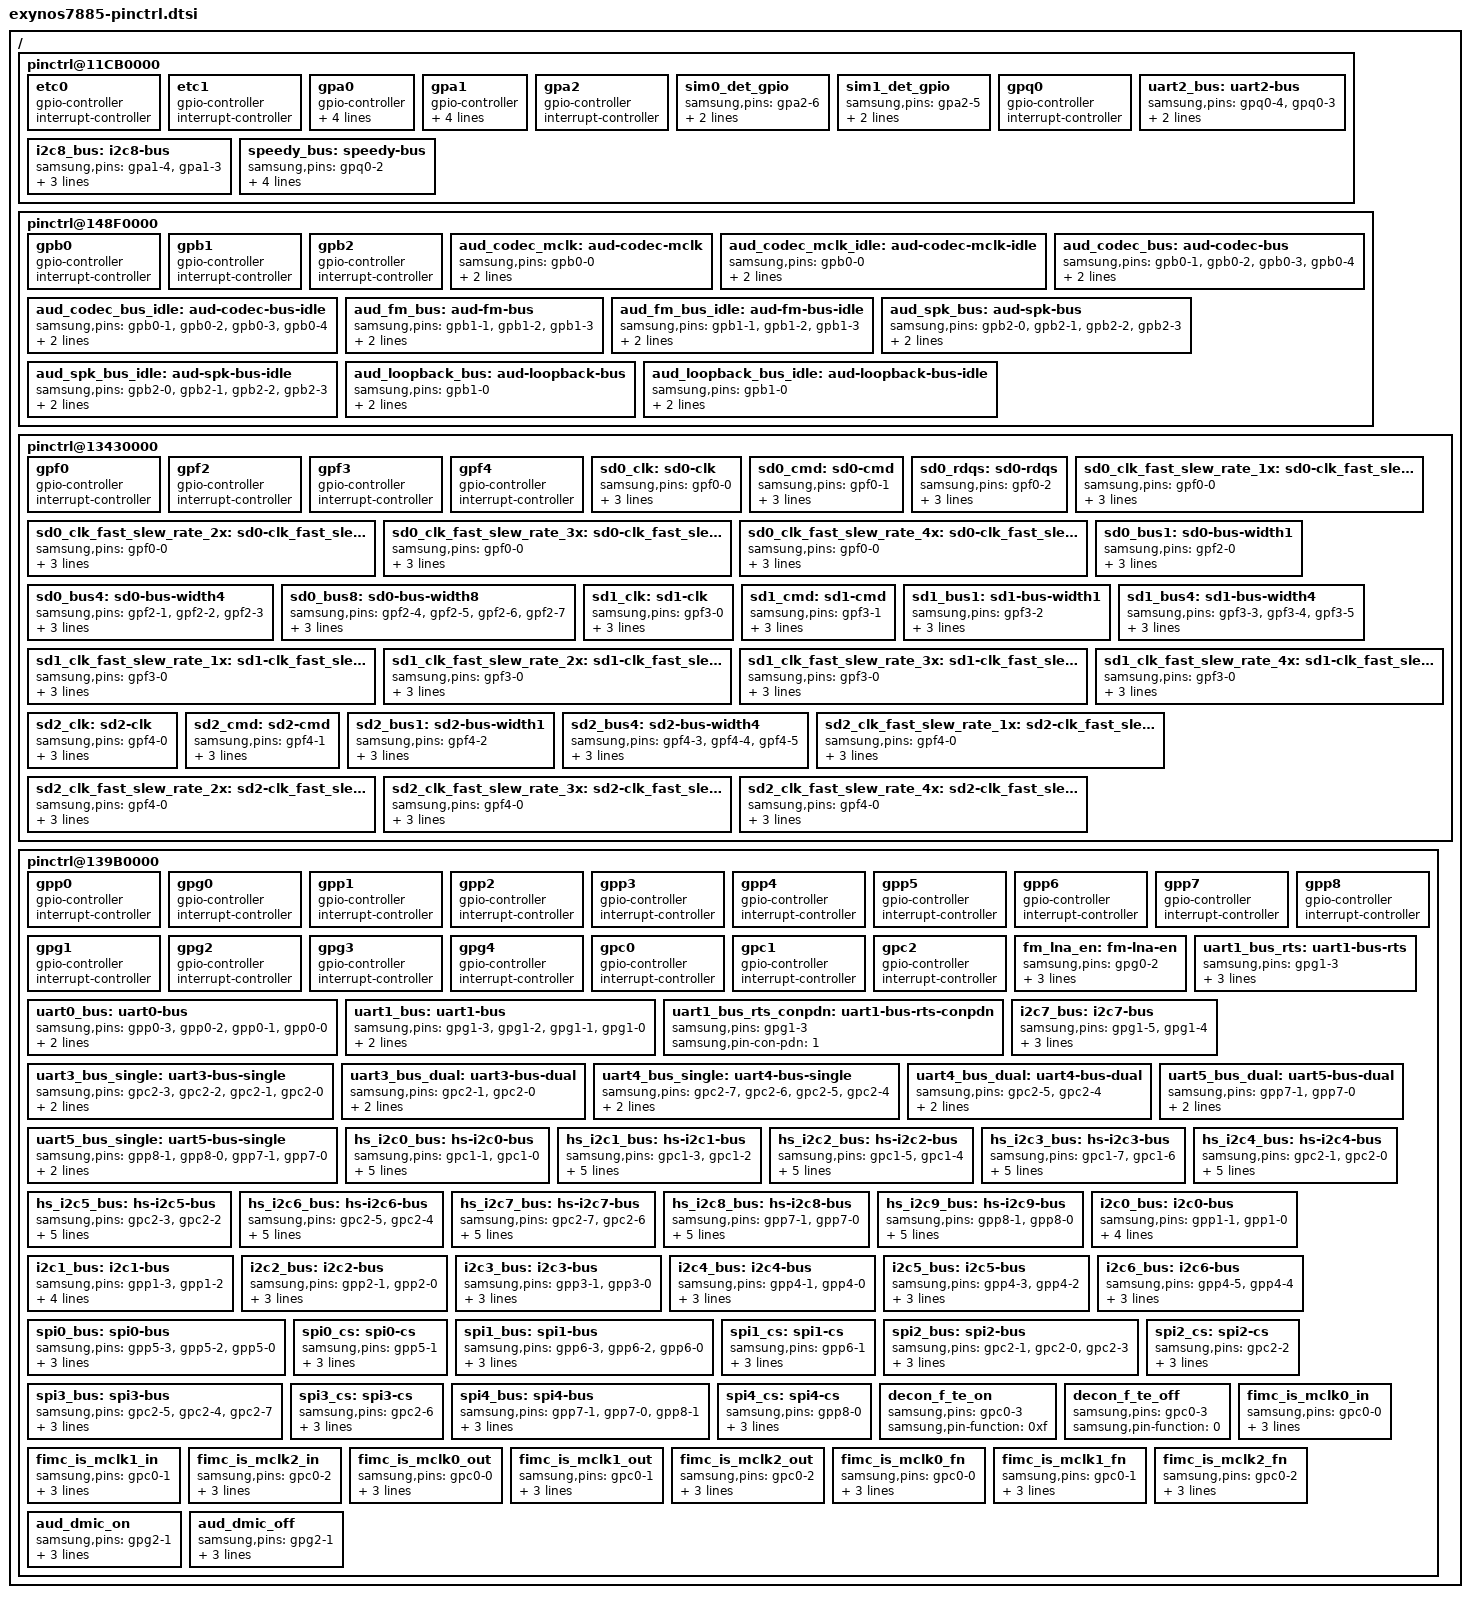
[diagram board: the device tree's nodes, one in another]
/*
 * Samsung's Exynos7885 SoC pin-mux and pin-config device tree source
 *
 * Copyright (c) 2017 Samsung Electronics Co., Ltd.
 *		http://www.samsung.com
 *
 * Samsung's Exynos7885 SoC pin-mux and pin-config options are listed as device
 * tree nodes are listed in this file.
 *
 * This program is free software; you can redistribute it and/or modify
 * it under the terms of the GNU General Public License version 2 as
 * published by the Free Software Foundation.
*/

/ {
	/* ALIVE */
	pinctrl@11CB0000 {
                etc0: etc0 {
                        gpio-controller;
                        #gpio-cells = <2>;

                        interrupt-controller;
                        #interrupt-cells = <2>;
                };

                etc1: etc1 {
                        gpio-controller;
                        #gpio-cells = <2>;

                        interrupt-controller;
                        #interrupt-cells = <2>;
                };

		gpa0: gpa0 {
			gpio-controller;
			#gpio-cells = <2>;

			interrupt-controller;
			#interrupt-cells = <2>;
			interrupt-parent = <&gic>;
			interrupts = <0 0 0>, <0 1 0>, <0 2 0>, <0 3 0>,
				     <0 4 0>, <0 5 0>, <0 6 0>, <0 7 0>;
		};

		gpa1: gpa1 {
			gpio-controller;
			#gpio-cells = <2>;

			interrupt-controller;
			#interrupt-cells = <3>;
			interrupt-parent = <&gic>;
			interrupts = <0 8 0>, <0 9 0>, <0 10 0>, <0 11 0>,
				     <0 12 0>, <0 13 0>, <0 14 0>, <0 15 0>;
		};

		gpa2: gpa2 {
			gpio-controller;
			#gpio-cells = <2>;

			interrupt-controller;
			#interrupt-cells = <2>;
		};

		sim0_det_gpio: sim0_det_gpio {
			samsung,pins = "gpa2-6";
			samsung,pin-function = <15>;
			samsung,pin-pud = <0>;
		};

		sim1_det_gpio: sim1_det_gpio {
			samsung,pins = "gpa2-5";
			samsung,pin-function = <15>;
			samsung,pin-pud = <0>;
		};

		gpq0: gpq0 {
			gpio-controller;
			#gpio-cells = <2>;

			interrupt-controller;
			#interrupt-cells = <2>;
		};

		/* UART_DEBUG */
		uart2_bus: uart2-bus {
			samsung,pins = "gpq0-4", "gpq0-3";
			samsung,pin-function = <2>;
			samsung,pin-pud = <0>;
		};

		/* I2C_APM */
		i2c8_bus: i2c8-bus {
			samsung,pins = "gpa1-4", "gpa1-3";
			samsung,pin-function = <2>;
			samsung,pin-pud = <3>;
			samsung,pin-drv = <0>;
		};

		speedy_bus: speedy-bus {
			samsung,pins = "gpq0-2";
			samsung,pin-function = <2>;
			samsung,pin-con-pdn = <3>;
			samsung,pin-pud = <3>;
			samsung,pin-drv = <0>;
		};
	};

	/* DISPAUD */
	pinctrl@148F0000 {
		gpb0: gpb0 {
			gpio-controller;
			#gpio-cells = <2>;

			interrupt-controller;
			#interrupt-cells = <2>;
		};

		gpb1: gpb1 {
			gpio-controller;
			#gpio-cells = <2>;

			interrupt-controller;
			#interrupt-cells = <2>;
		};

		gpb2: gpb2 {
			gpio-controller;
			#gpio-cells = <2>;

			interrupt-controller;
			#interrupt-cells = <2>;
		};

		aud_codec_mclk: aud-codec-mclk {
			samsung,pins = "gpb0-0";
			samsung,pin-function = <2>;
			samsung,pin-pud = <1>;
		};

		aud_codec_mclk_idle: aud-codec-mclk-idle {
			samsung,pins = "gpb0-0";
			samsung,pin-function = <0>;
			samsung,pin-pud = <1>;
		};

		aud_codec_bus: aud-codec-bus {
			samsung,pins = "gpb0-1", "gpb0-2", "gpb0-3", "gpb0-4";
			samsung,pin-function = <2>;
			samsung,pin-pud = <1>;
		};

		aud_codec_bus_idle: aud-codec-bus-idle {
			samsung,pins = "gpb0-1", "gpb0-2", "gpb0-3", "gpb0-4";
			samsung,pin-function = <0>;
			samsung,pin-pud = <1>;
		};

		aud_fm_bus: aud-fm-bus {
			samsung,pins = "gpb1-1", "gpb1-2", "gpb1-3";
			samsung,pin-function = <2>;
			samsung,pin-pud = <1>;
		};

		aud_fm_bus_idle: aud-fm-bus-idle {
			samsung,pins = "gpb1-1", "gpb1-2", "gpb1-3";
			samsung,pin-function = <0>;
			samsung,pin-pud = <1>;
		};

		aud_spk_bus: aud-spk-bus {
			samsung,pins = "gpb2-0", "gpb2-1", "gpb2-2", "gpb2-3";
			samsung,pin-function = <2>;
			samsung,pin-pud = <1>;
		};

		aud_spk_bus_idle: aud-spk-bus-idle {
			samsung,pins = "gpb2-0", "gpb2-1", "gpb2-2", "gpb2-3";
			samsung,pin-function = <0>;
			samsung,pin-pud = <1>;
		};

		aud_loopback_bus: aud-loopback-bus{
			samsung,pins = "gpb1-0";
			samsung,pin-function = <2>;
			samsung,pin-pud = <1>;
		};

		aud_loopback_bus_idle: aud-loopback-bus-idle{
			samsung,pins = "gpb1-0";
			samsung,pin-function = <0>;
			samsung,pin-pud = <1>;
		};
	};


	/* FSYS */
	pinctrl@13430000 {
		gpf0: gpf0 {
			gpio-controller;
			#gpio-cells = <2>;

			interrupt-controller;
			#interrupt-cells = <2>;
		};

		gpf2: gpf2 {
			gpio-controller;
			#gpio-cells = <2>;

			interrupt-controller;
			#interrupt-cells = <2>;
		};

		gpf3: gpf3 {
			gpio-controller;
			#gpio-cells = <2>;

			interrupt-controller;
			#interrupt-cells = <2>;
		};

		gpf4: gpf4 {
			gpio-controller;
			#gpio-cells = <2>;

			interrupt-controller;
			#interrupt-cells = <2>;
		};

		sd0_clk: sd0-clk {
			samsung,pins = "gpf0-0";
			samsung,pin-function = <2>;
			samsung,pin-pud = <0>;
			samsung,pin-drv = <3>;
		};

		sd0_cmd: sd0-cmd {
			samsung,pins = "gpf0-1";
			samsung,pin-function = <2>;
			samsung,pin-pud = <3>;
			samsung,pin-drv = <3>;
		};

		sd0_rdqs: sd0-rdqs {
			samsung,pins = "gpf0-2";
			samsung,pin-function = <2>;
			samsung,pin-pud = <1>;
			samsung,pin-drv = <3>;
		};

		sd0_clk_fast_slew_rate_1x: sd0-clk_fast_slew_rate_1x {
			samsung,pins = "gpf0-0";
			samsung,pin-function = <2>;
			samsung,pin-pud = <0>;
			samsung,pin-drv = <0>;
		};

		sd0_clk_fast_slew_rate_2x: sd0-clk_fast_slew_rate_2x {
			samsung,pins = "gpf0-0";
			samsung,pin-function = <2>;
			samsung,pin-pud = <0>;
			samsung,pin-drv = <1>;
		};

		sd0_clk_fast_slew_rate_3x: sd0-clk_fast_slew_rate_3x {
			samsung,pins = "gpf0-0";
			samsung,pin-function = <2>;
			samsung,pin-pud = <0>;
			samsung,pin-drv = <2>;
		};

		sd0_clk_fast_slew_rate_4x: sd0-clk_fast_slew_rate_4x {
			samsung,pins = "gpf0-0";
			samsung,pin-function = <2>;
			samsung,pin-pud = <0>;
			samsung,pin-drv = <3>;
		};

		sd0_bus1: sd0-bus-width1 {
			samsung,pins = "gpf2-0";
			samsung,pin-function = <2>;
			samsung,pin-pud = <3>;
			samsung,pin-drv = <3>;
		};

		sd0_bus4: sd0-bus-width4 {
			samsung,pins = "gpf2-1", "gpf2-2", "gpf2-3";
			samsung,pin-function = <2>;
			samsung,pin-pud = <3>;
			samsung,pin-drv = <3>;
		};

		sd0_bus8: sd0-bus-width8 {
			samsung,pins = "gpf2-4", "gpf2-5", "gpf2-6", "gpf2-7";
			samsung,pin-function = <2>;
			samsung,pin-pud = <3>;
			samsung,pin-drv = <3>;
		};

		sd1_clk: sd1-clk {
			samsung,pins = "gpf3-0";
			samsung,pin-function = <2>;
			samsung,pin-pud = <0>;
			samsung,pin-drv = <2>;
		};

		sd1_cmd: sd1-cmd {
			samsung,pins = "gpf3-1";
			samsung,pin-function = <2>;
			samsung,pin-pud = <3>;
			samsung,pin-drv = <2>;
		};

		sd1_bus1: sd1-bus-width1 {
			samsung,pins = "gpf3-2";
			samsung,pin-function = <2>;
			samsung,pin-pud = <3>;
			samsung,pin-drv = <2>;
		};

		sd1_bus4: sd1-bus-width4 {
			samsung,pins = "gpf3-3", "gpf3-4", "gpf3-5";
			samsung,pin-function = <2>;
			samsung,pin-pud = <3>;
			samsung,pin-drv = <2>;
		};

		sd1_clk_fast_slew_rate_1x: sd1-clk_fast_slew_rate_1x {
			samsung,pins = "gpf3-0";
			samsung,pin-function = <2>;
			samsung,pin-pud = <0>;
			samsung,pin-drv = <0>;
		};

		sd1_clk_fast_slew_rate_2x: sd1-clk_fast_slew_rate_2x {
			samsung,pins = "gpf3-0";
			samsung,pin-function = <2>;
			samsung,pin-pud = <0>;
			samsung,pin-drv = <1>;
		};

		sd1_clk_fast_slew_rate_3x: sd1-clk_fast_slew_rate_3x {
			samsung,pins = "gpf3-0";
			samsung,pin-function = <2>;
			samsung,pin-pud = <0>;
			samsung,pin-drv = <2>;
		};

		sd1_clk_fast_slew_rate_4x: sd1-clk_fast_slew_rate_4x {
			samsung,pins = "gpf3-0";
			samsung,pin-function = <2>;
			samsung,pin-pud = <0>;
			samsung,pin-drv = <3>;
		};

		sd2_clk: sd2-clk {
			samsung,pins = "gpf4-0";
			samsung,pin-function = <2>;
			samsung,pin-pud = <0>;
			samsung,pin-drv = <2>;
		};

		sd2_cmd: sd2-cmd {
			samsung,pins = "gpf4-1";
			samsung,pin-function = <2>;
			samsung,pin-pud = <3>;
			samsung,pin-drv = <2>;
		};

		sd2_bus1: sd2-bus-width1 {
			samsung,pins = "gpf4-2";
			samsung,pin-function = <2>;
			samsung,pin-pud = <3>;
			samsung,pin-drv = <2>;
		};

		sd2_bus4: sd2-bus-width4 {
			samsung,pins = "gpf4-3", "gpf4-4", "gpf4-5";
			samsung,pin-function = <2>;
			samsung,pin-pud = <3>;
			samsung,pin-drv = <2>;
		};

		sd2_clk_fast_slew_rate_1x: sd2-clk_fast_slew_rate_1x {
			samsung,pins = "gpf4-0";
			samsung,pin-function = <2>;
			samsung,pin-pud = <0>;
			samsung,pin-drv = <0>;
		};

		sd2_clk_fast_slew_rate_2x: sd2-clk_fast_slew_rate_2x {
			samsung,pins = "gpf4-0";
			samsung,pin-function = <2>;
			samsung,pin-pud = <0>;
			samsung,pin-drv = <1>;
		};

		sd2_clk_fast_slew_rate_3x: sd2-clk_fast_slew_rate_3x {
			samsung,pins = "gpf4-0";
			samsung,pin-function = <2>;
			samsung,pin-pud = <0>;
			samsung,pin-drv = <2>;
		};

		sd2_clk_fast_slew_rate_4x: sd2-clk_fast_slew_rate_4x {
			samsung,pins = "gpf4-0";
			samsung,pin-function = <2>;
			samsung,pin-pud = <0>;
			samsung,pin-drv = <3>;
		};
	};

	/* TOP */
	pinctrl@139B0000 {
		gpp0: gpp0 {
			gpio-controller;
			#gpio-cells = <2>;

			interrupt-controller;
			#interrupt-cells = <2>;
		};

		gpg0: gpg0 {
			gpio-controller;
			#gpio-cells = <2>;

			interrupt-controller;
			#interrupt-cells = <2>;
		};

		gpp1: gpp1 {
			gpio-controller;
			#gpio-cells = <2>;

			interrupt-controller;
			#interrupt-cells = <2>;
		};

		gpp2: gpp2 {
			gpio-controller;
			#gpio-cells = <2>;

			interrupt-controller;
			#interrupt-cells = <2>;
		};

		gpp3: gpp3 {
			gpio-controller;
			#gpio-cells = <2>;

			interrupt-controller;
			#interrupt-cells = <2>;
		};

		gpp4: gpp4 {
			gpio-controller;
			#gpio-cells = <2>;

			interrupt-controller;
			#interrupt-cells = <2>;
		};

		gpp5: gpp5 {
			gpio-controller;
			#gpio-cells = <2>;

			interrupt-controller;
			#interrupt-cells = <2>;
		};

		gpp6: gpp6 {
			gpio-controller;
			#gpio-cells = <2>;

			interrupt-controller;
			#interrupt-cells = <2>;
		};

		gpp7: gpp7 {
			gpio-controller;
			#gpio-cells = <2>;

			interrupt-controller;
			#interrupt-cells = <2>;
		};

		gpp8: gpp8 {
			gpio-controller;
			#gpio-cells = <2>;

			interrupt-controller;
			#interrupt-cells = <2>;
		};

		gpg1: gpg1 {
			gpio-controller;
			#gpio-cells = <2>;

			interrupt-controller;
			#interrupt-cells = <2>;
		};

		gpg2: gpg2 {
			gpio-controller;
			#gpio-cells = <2>;

			interrupt-controller;
			#interrupt-cells = <2>;
		};

		gpg3: gpg3 {
			gpio-controller;
			#gpio-cells = <2>;

			interrupt-controller;
			#interrupt-cells = <2>;
		};

		gpg4: gpg4 {
			gpio-controller;
			#gpio-cells = <2>;

			interrupt-controller;
			#interrupt-cells = <2>;
		};

		gpc0: gpc0 {
			gpio-controller;
			#gpio-cells = <2>;

			interrupt-controller;
			#interrupt-cells = <2>;
		};

		gpc1: gpc1 {
			gpio-controller;
			#gpio-cells = <2>;

			interrupt-controller;
			#interrupt-cells = <2>;
		};

		gpc2: gpc2 {
			gpio-controller;
			#gpio-cells = <2>;

			interrupt-controller;
			#interrupt-cells = <2>;
		};

		fm_lna_en: fm-lna-en {
			samsung,pins = "gpg0-2";
			samsung,pin-function = <1>;
			samsung,pin-pud = <0>;
			samsung,pin-val = <0>;
		};

		/* UART_HEALTH */
		uart0_bus: uart0-bus {
			samsung,pins = "gpp0-3", "gpp0-2", "gpp0-1", "gpp0-0";
			samsung,pin-function = <2>;
			samsung,pin-pud = <0>;
		   };

		/* UART_BTWIFIFM */
		uart1_bus: uart1-bus {
			samsung,pins = "gpg1-3", "gpg1-2", "gpg1-1", "gpg1-0";
			samsung,pin-function = <2>;
			samsung,pin-pud = <0>;
		};

		uart1_bus_rts_conpdn: uart1-bus-rts-conpdn{
			samsung,pins = "gpg1-3";
			samsung,pin-con-pdn = <1>;
		};

		uart1_bus_rts: uart1-bus-rts {
			samsung,pins = "gpg1-3";
			samsung,pin-function = <1>;
			samsung,pin-pud = <0>;
			samsung,pin-val = <1>;
		};

		/* I2C_BUS */
		i2c7_bus: i2c7-bus {
			samsung,pins = "gpg1-5", "gpg1-4";
			samsung,pin-function = <2>;
			samsung,pin-pud = <3>;
			samsung,pin-drv = <0>;
		};

		/* USI0 */
		uart3_bus_single: uart3-bus-single {
			samsung,pins = "gpc2-3", "gpc2-2", "gpc2-1", "gpc2-0";
			samsung,pin-function = <2>;
			samsung,pin-pud = <0>;
		  };

		/* USI0 */
		uart3_bus_dual: uart3-bus-dual {
			samsung,pins = "gpc2-1", "gpc2-0";
			samsung,pin-function = <2>;
			samsung,pin-pud = <0>;
		};

		/* USI1 */
		uart4_bus_single: uart4-bus-single {
			samsung,pins = "gpc2-7", "gpc2-6", "gpc2-5", "gpc2-4";
			samsung,pin-function = <2>;
			samsung,pin-pud = <0>;
		  };

		/* USI1 */
		uart4_bus_dual: uart4-bus-dual {
			samsung,pins = "gpc2-5", "gpc2-4";
			samsung,pin-function = <2>;
			samsung,pin-pud = <0>;
		};

		/* USI2 */
		uart5_bus_single: uart5-bus-single {
			samsung,pins = "gpp8-1", "gpp8-0", "gpp7-1", "gpp7-0";
			samsung,pin-function = <2>;
			samsung,pin-pud = <0>;
		  };

		/* USI2 */
		uart5_bus_dual: uart5-bus-dual {
			samsung,pins = "gpp7-1", "gpp7-0";
			samsung,pin-function = <2>;
			samsung,pin-pud = <0>;
		};

		/* HSI2C_REARSENSOR */
		hs_i2c0_bus: hs-i2c0-bus {
			samsung,pins = "gpc1-1", "gpc1-0";
			samsung,pin-function = <2>;
			samsung,pin-con-pdn = <1>;
			samsung,pin-pud-pdn = <3>;
			samsung,pin-pud = <0>;
			samsung,pin-drv = <0>;
		};

		/* HSI2C_REARAF */
		hs_i2c1_bus: hs-i2c1-bus {
			samsung,pins = "gpc1-3", "gpc1-2";
			samsung,pin-function = <2>;
			samsung,pin-pud = <0>;
			samsung,pin-drv = <0>;
			samsung,pin-con-pdn = <1>;
			samsung,pin-pud-pdn = <3>;
		};

		/* HSI2C_FRONTSENSOR */
		hs_i2c2_bus: hs-i2c2-bus {
			samsung,pins = "gpc1-5", "gpc1-4";
			samsung,pin-function = <2>;
			samsung,pin-pud = <0>;
			samsung,pin-drv = <0>;
			samsung,pin-con-pdn = <1>;
			samsung,pin-pud-pdn = <3>;
		};

		/* HSI2C_REARSENSOR */
		hs_i2c3_bus: hs-i2c3-bus {
			samsung,pins = "gpc1-7", "gpc1-6";
			samsung,pin-function = <2>;
			samsung,pin-pud = <0>;
			samsung,pin-drv = <0>;
			samsung,pin-con-pdn = <1>;
			samsung,pin-pud-pdn = <3>;
		};

		/* USI0_CH0 */
		hs_i2c4_bus: hs-i2c4-bus {
			samsung,pins = "gpc2-1", "gpc2-0";
			samsung,pin-function = <2>;
			samsung,pin-pud = <0>;
			samsung,pin-drv = <0>;
			samsung,pin-con-pdn = <1>;
			samsung,pin-pud-pdn = <3>;
		};

		/* USI0_CH1 */
		hs_i2c5_bus: hs-i2c5-bus {
			samsung,pins = "gpc2-3", "gpc2-2";
			samsung,pin-function = <2>;
			samsung,pin-pud = <0>;
			samsung,pin-drv = <0>;
			samsung,pin-con-pdn = <1>;
			samsung,pin-pud-pdn = <3>;
		};

		/* USI1_CH0 */
		hs_i2c6_bus: hs-i2c6-bus {
			samsung,pins = "gpc2-5", "gpc2-4";
			samsung,pin-function = <2>;
			samsung,pin-pud = <0>;
			samsung,pin-drv = <0>;
			samsung,pin-con-pdn = <1>;
			samsung,pin-pud-pdn = <3>;
		};

		/* USI1_CH1 */
		hs_i2c7_bus: hs-i2c7-bus {
			samsung,pins = "gpc2-7", "gpc2-6";
			samsung,pin-function = <2>;
			samsung,pin-pud = <0>;
			samsung,pin-drv = <0>;
			samsung,pin-con-pdn = <1>;
			samsung,pin-pud-pdn = <3>;
		};

		/* USI2_CH0 */
		hs_i2c8_bus: hs-i2c8-bus {
			samsung,pins = "gpp7-1", "gpp7-0";
			samsung,pin-function = <2>;
			samsung,pin-pud = <0>;
			samsung,pin-drv = <0>;
			samsung,pin-con-pdn = <1>;
			samsung,pin-pud-pdn = <3>;
		};

		/* USI2_CH1 */
		hs_i2c9_bus: hs-i2c9-bus {
			samsung,pins = "gpp8-1", "gpp8-0";
			samsung,pin-function = <2>;
			samsung,pin-pud = <0>;
			samsung,pin-drv = <0>;
			samsung,pin-con-pdn = <1>;
			samsung,pin-pud-pdn = <3>;
		};

		/* I2C_FUELGAUGE */
		i2c0_bus: i2c0-bus {
			samsung,pins = "gpp1-1", "gpp1-0";
			samsung,pin-function = <2>;
			samsung,pin-con-pdn = <3>;
			samsung,pin-pud = <3>;
			samsung,pin-drv = <0>;
		};

		/* I2C_CHARGER */
		i2c1_bus: i2c1-bus {
			samsung,pins = "gpp1-3", "gpp1-2";
			samsung,pin-function = <2>;
			samsung,pin-con-pdn = <3>;
			samsung,pin-pud = <3>;
			samsung,pin-drv = <0>;
		};

		/* I2C_TOUCHKEY */
		i2c2_bus: i2c2-bus {
			samsung,pins = "gpp2-1", "gpp2-0";
			samsung,pin-function = <2>;
			samsung,pin-pud = <3>;
			samsung,pin-drv = <0>;
		};

		/* I2C_SPKAMP */
		i2c3_bus: i2c3-bus {
			samsung,pins = "gpp3-1", "gpp3-0";
			samsung,pin-function = <2>;
			samsung,pin-pud = <3>;
			samsung,pin-drv = <0>;
		};

		/* I2C_MUIC */
		i2c4_bus: i2c4-bus {
			samsung,pins = "gpp4-1", "gpp4-0";
			samsung,pin-function = <2>;
			samsung,pin-pud = <3>;
			samsung,pin-drv = <0>;
		};

		/* I2C_NFC */
		i2c5_bus: i2c5-bus {
			samsung,pins = "gpp4-3", "gpp4-2";
			samsung,pin-function = <2>;
			samsung,pin-pud = <3>;
			samsung,pin-drv = <0>;
		};

		/* I2C_IFPMIC */
		i2c6_bus: i2c6-bus {
			samsung,pins = "gpp4-5", "gpp4-4";
			samsung,pin-function = <2>;
			samsung,pin-pud = <3>;
			samsung,pin-drv = <0>;
		};

		/* SPI_ESE */
		spi0_bus: spi0-bus {
			samsung,pins = "gpp5-3", "gpp5-2", "gpp5-0";
			samsung,pin-function = <2>;
			samsung,pin-pud = <3>;
			samsung,pin-drv = <0>;
		};

		spi0_cs: spi0-cs {
			samsung,pins = "gpp5-1";
			samsung,pin-function = <1>;
			samsung,pin-pud = <3>;
			samsung,pin-drv = <0>;
		};

		/* SPI_FP */
		spi1_bus: spi1-bus {
			samsung,pins = "gpp6-3", "gpp6-2", "gpp6-0";
			samsung,pin-function = <2>;
			samsung,pin-pud = <3>;
			samsung,pin-drv = <0>;
		};

		spi1_cs: spi1-cs {
			samsung,pins = "gpp6-1";
			samsung,pin-function = <1>;
			samsung,pin-pud = <3>;
			samsung,pin-drv = <0>;
		};

		/* SPI USI0 */
		spi2_bus: spi2-bus {
			samsung,pins = "gpc2-1", "gpc2-0", "gpc2-3";
			samsung,pin-function = <2>;
			samsung,pin-pud = <3>;
			samsung,pin-drv = <0>;
		};

		spi2_cs: spi2-cs {
			samsung,pins = "gpc2-2";
			samsung,pin-function = <1>;
			samsung,pin-pud = <3>;
			samsung,pin-drv = <0>;
		};

		/* SPI USI1 */
		spi3_bus: spi3-bus {
			samsung,pins = "gpc2-5", "gpc2-4", "gpc2-7";
			samsung,pin-function = <2>;
			samsung,pin-pud = <3>;
			samsung,pin-drv = <0>;
		};

		spi3_cs: spi3-cs {
			samsung,pins = "gpc2-6";
			samsung,pin-function = <1>;
			samsung,pin-pud = <3>;
			samsung,pin-drv = <0>;
		};

		/* SPI USI2 */
		spi4_bus: spi4-bus {
			samsung,pins = "gpp7-1", "gpp7-0", "gpp8-1";
			samsung,pin-function = <2>;
			samsung,pin-pud = <3>;
			samsung,pin-drv = <0>;
		};

		spi4_cs: spi4-cs {
			samsung,pins = "gpp8-0";
			samsung,pin-function = <1>;
			samsung,pin-pud = <3>;
			samsung,pin-drv = <0>;
		};

		/* DECON TE */
		decon_f_te_on: decon_f_te_on {
			samsung,pins = "gpc0-3";
			samsung,pin-function = <0xf>;
		};

		decon_f_te_off: decon_f_te_off {
			samsung,pins = "gpc0-3";
			samsung,pin-function = <0>;
		};

		fimc_is_mclk0_in: fimc_is_mclk0_in {
			samsung,pins = "gpc0-0";
			samsung,pin-function = <0>;
			samsung,pin-pud = <0>;
			samsung,pin-drv = <2>;
		};

		fimc_is_mclk1_in: fimc_is_mclk1_in {
			samsung,pins = "gpc0-1";
			samsung,pin-function = <0>;
			samsung,pin-pud = <0>;
			samsung,pin-drv = <2>;
		};

		fimc_is_mclk2_in: fimc_is_mclk2_in {
			samsung,pins = "gpc0-2";
			samsung,pin-function = <0>;
			samsung,pin-pud = <0>;
			samsung,pin-drv = <2>;
		};

		fimc_is_mclk0_out: fimc_is_mclk0_out {
			samsung,pins = "gpc0-0";
			samsung,pin-function = <1>;
			samsung,pin-pud = <0>;
			samsung,pin-drv = <2>;
		};

		fimc_is_mclk1_out: fimc_is_mclk1_out {
			samsung,pins = "gpc0-1";
			samsung,pin-function = <1>;
			samsung,pin-pud = <0>;
			samsung,pin-drv = <2>;
		};

		fimc_is_mclk2_out: fimc_is_mclk2_out {
			samsung,pins = "gpc0-2";
			samsung,pin-function = <1>;
			samsung,pin-pud = <0>;
			samsung,pin-drv = <2>;
		};

		fimc_is_mclk0_fn: fimc_is_mclk0_fn {
			samsung,pins = "gpc0-0";
			samsung,pin-function = <2>;
			samsung,pin-pud = <0>;
			samsung,pin-drv = <2>;
		};

		fimc_is_mclk1_fn: fimc_is_mclk1_fn {
			samsung,pins = "gpc0-1";
			samsung,pin-function = <2>;
			samsung,pin-pud = <0>;
			samsung,pin-drv = <2>;
		};

		fimc_is_mclk2_fn: fimc_is_mclk2_fn {
			samsung,pins = "gpc0-2";
			samsung,pin-function = <2>;
			samsung,pin-pud = <0>;
			samsung,pin-drv = <2>;
		};

		aud_dmic_on: aud_dmic_on {
			samsung,pins = "gpg2-1";
			samsung,pin-function = <1>;
			samsung,pin-con-pdn = <3>;
			samsung,pin-val = <1>;
		};

		aud_dmic_off: aud_dmic_off {
			samsung,pins = "gpg2-1";
			samsung,pin-function = <1>;
			samsung,pin-con-pdn = <3>;
			samsung,pin-val = <0>;
		};
	};
};
